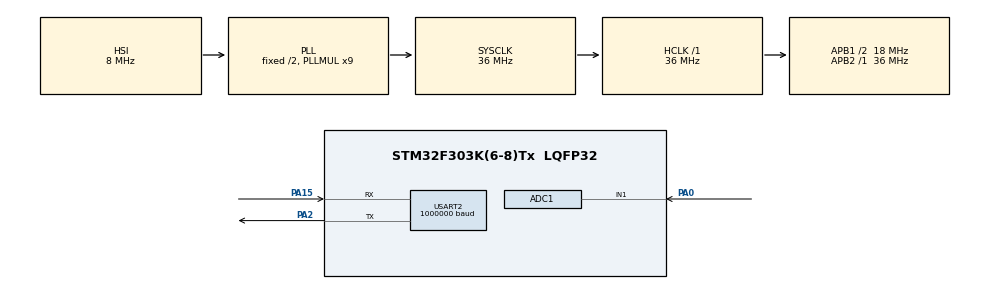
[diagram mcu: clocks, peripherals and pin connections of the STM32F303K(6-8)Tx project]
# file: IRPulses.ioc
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ADC1.Channel-0\#ChannelRegularConversion=ADC_CHANNEL_1
ADC1.ExternalTrigConv=ADC_EXTERNALTRIGCONV_T1_TRGO
ADC1.NbrOfConversionFlag=1
ADC1.Offset-0\#ChannelRegularConversion=0
ADC1.OffsetNumber-0\#ChannelRegularConversion=ADC_OFFSET_NONE
ADC1.Rank-0\#ChannelRegularConversion=1
ADC1.Resolution=ADC_RESOLUTION_8B
ADC1.SamplingTime-0\#ChannelRegularConversion=ADC_SAMPLETIME_1CYCLE_5
ADC1.master=1
Dma.ADC1.0.Direction=DMA_PERIPH_TO_MEMORY
Dma.ADC1.0.Instance=DMA1_Channel1
Dma.ADC1.0.MemDataAlignment=DMA_MDATAALIGN_HALFWORD
Dma.ADC1.0.MemInc=DMA_MINC_ENABLE
Dma.ADC1.0.Mode=DMA_NORMAL
Dma.ADC1.0.PeriphDataAlignment=DMA_PDATAALIGN_HALFWORD
Dma.ADC1.0.PeriphInc=DMA_PINC_DISABLE
Dma.ADC1.0.Priority=DMA_PRIORITY_LOW
Dma.Request0=ADC1
Mcu.Family=STM32F3
Mcu.Name=STM32F303K(6-8)Tx
Mcu.Package=LQFP32
NVIC.ADC1_2_IRQn=true\:0\:0\:false\:false\:true\:true\:true\:true
NVIC.DMA1_Channel1_IRQn=true\:0\:0\:false\:false\:true\:false\:true\:true
NVIC.PriorityGroup=NVIC_PRIORITYGROUP_4
PA0.Mode=IN1-Single-Ended
PA0.Signal=ADC1_IN1
PA13.Mode=Serial_Wire
PA13.Signal=SYS_JTMS-SWDIO
PA14.Mode=Serial_Wire
PA14.Signal=SYS_JTCK-SWCLK
PA15.Mode=Asynchronous
PA15.Signal=USART2_RX
PA2.Mode=Asynchronous
PA2.Signal=USART2_TX
PF0\ /\ OSC_IN.Mode=HSE-External-Clock-Source
PF0\ /\ OSC_IN.Signal=RCC_OSC_IN
ProjectManager.HeapSize=0x200
ProjectManager.StackSize=0x400
ProjectManager.TargetToolchain=Makefile
RCC.AHBFreq_Value=36000000
RCC.APB1CLKDivider=RCC_HCLK_DIV2
RCC.APB1Freq_Value=18000000
RCC.APB1TimFreq_Value=36000000
RCC.APB2Freq_Value=36000000
RCC.APB2TimFreq_Value=36000000
RCC.CortexFreq_Value=36000000
RCC.HCLKFreq_Value=36000000
RCC.HSE_VALUE=8000000
RCC.HSI_VALUE=8000000
RCC.PLLMUL=RCC_PLL_MUL9
RCC.SYSCLKFreq_VALUE=36000000
RCC.SYSCLKSourceVirtual=RCC_SYSCLKSOURCE_PLLCLK
TIM1.Period=19
TIM1.Prescaler=35
TIM1.TIM_MasterOutputTrigger=TIM_TRGO_UPDATE
USART2.BaudRate=1000000
USART2.VirtualMode-Asynchronous=VM_ASYNC
VP_TIM1_VS_ClockSourceINT.Mode=Internal
board=custom

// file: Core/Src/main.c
/* USER CODE BEGIN Header */
/**
 ******************************************************************************
 * @file           : main.c
 * @brief          : Main program body
 ******************************************************************************
 * @attention
 *
 * Copyright (c) 2022 STMicroelectronics.
 * All rights reserved.
 *
 * This software is licensed under terms that can be found in the LICENSE file
 * in the root directory of this software component.
 * If no LICENSE file comes with this software, it is provided AS-IS.
 *
 ******************************************************************************
 */
/* USER CODE END Header */
#include "main.h"
#include "stm32f3xx_hal_adc.h"
#include "stm32f3xx_hal_adc_ex.h"
#include "stm32f3xx_hal_tim.h"

ADC_HandleTypeDef hadc1;
DMA_HandleTypeDef hdma_adc1;

TIM_HandleTypeDef htim1;

UART_HandleTypeDef huart2;

void SystemClock_Config(void);
static void MX_GPIO_Init(void);
static void MX_DMA_Init(void);
static void MX_USART2_UART_Init(void);
static void MX_ADC1_Init(void);
static void MX_TIM1_Init(void);

/* USER CODE BEGIN 0 */
uint16_t buf[1024];
uint32_t integral;
uint8_t complete;
uint8_t busy;

void HAL_ADC_ConvCpltCallback(ADC_HandleTypeDef *hadc) {
	complete = 1;
}
/* USER CODE END 0 */

int main(void) {

	/* MCU
	 * Configuration--------------------------------------------------------*/

	/* Reset of all peripherals, Initializes the Flash interface and the
	 * Systick. */
	HAL_Init();

	/* Configure the system clock */
	SystemClock_Config();

	/* Initialize all configured peripherals */
	MX_GPIO_Init();
	MX_DMA_Init();
	MX_USART2_UART_Init();
	MX_ADC1_Init();
	MX_TIM1_Init();

	/* Infinite loop */
	/* USER CODE BEGIN WHILE */
	/* __HAL_TIM_SET_PRESCALER(&htim1, */
	/* 						35000); // slow down the timer for testing purposes */

	hadc1.Init.ExternalTrigConv = ADC_SOFTWARE_START;
	HAL_ADC_Init(&hadc1);
	while (1) {
		if (complete) {
			HAL_TIM_Base_Stop(&htim1);
			complete = 0;
			busy = 0;
			integral = 0;
			for (uint16_t i = 0; i < sizeof(buf) / sizeof(*buf); i++) {
				integral += buf[i];
			}
			hadc1.Init.ExternalTrigConv = ADC_SOFTWARE_START;
			HAL_ADC_Init(&hadc1);
			__BKPT();
		} else if (!busy) {
			HAL_ADC_Start(&hadc1);
			HAL_ADC_PollForConversion(&hadc1, 1500);
			uint16_t val = HAL_ADC_GetValue(&hadc1);

			if (val >= 32) {
				busy = 1;
				hadc1.Init.ExternalTrigConv = ADC_EXTERNALTRIGCONV_T1_TRGO;
				HAL_ADC_Init(&hadc1);
				HAL_ADC_Start_DMA(&hadc1, buf, 1024);
				HAL_TIM_Base_Start(&htim1);
			}
		}

		/* USER CODE END WHILE */

	}
}

void SystemClock_Config(void) {
	RCC_OscInitTypeDef RCC_OscInitStruct = {0};
	RCC_ClkInitTypeDef RCC_ClkInitStruct = {0};
	RCC_PeriphCLKInitTypeDef PeriphClkInit = {0};

	/** Initializes the RCC Oscillators according to the specified parameters
	 * in the RCC_OscInitTypeDef structure.
	 */
	RCC_OscInitStruct.OscillatorType = RCC_OSCILLATORTYPE_HSI;
	RCC_OscInitStruct.HSIState = RCC_HSI_ON;
	RCC_OscInitStruct.HSICalibrationValue = RCC_HSICALIBRATION_DEFAULT;
	RCC_OscInitStruct.PLL.PLLState = RCC_PLL_ON;
	RCC_OscInitStruct.PLL.PLLSource = RCC_PLLSOURCE_HSI;
	RCC_OscInitStruct.PLL.PLLMUL = RCC_PLL_MUL9;
	if (HAL_RCC_OscConfig(&RCC_OscInitStruct) != HAL_OK) {
		Error_Handler();
	}

	/** Initializes the CPU, AHB and APB buses clocks
	 */
	RCC_ClkInitStruct.ClockType = RCC_CLOCKTYPE_HCLK | RCC_CLOCKTYPE_SYSCLK |
								  RCC_CLOCKTYPE_PCLK1 | RCC_CLOCKTYPE_PCLK2;
	RCC_ClkInitStruct.SYSCLKSource = RCC_SYSCLKSOURCE_PLLCLK;
	RCC_ClkInitStruct.AHBCLKDivider = RCC_SYSCLK_DIV1;
	RCC_ClkInitStruct.APB1CLKDivider = RCC_HCLK_DIV2;
	RCC_ClkInitStruct.APB2CLKDivider = RCC_HCLK_DIV1;

	if (HAL_RCC_ClockConfig(&RCC_ClkInitStruct, FLASH_LATENCY_1) != HAL_OK) {
		Error_Handler();
	}
	PeriphClkInit.PeriphClockSelection =
		RCC_PERIPHCLK_TIM1 | RCC_PERIPHCLK_ADC12;
	PeriphClkInit.Adc12ClockSelection = RCC_ADC12PLLCLK_DIV1;
	PeriphClkInit.Tim1ClockSelection = RCC_TIM1CLK_HCLK;
	if (HAL_RCCEx_PeriphCLKConfig(&PeriphClkInit) != HAL_OK) {
		Error_Handler();
	}
}

static void MX_ADC1_Init(void) {

	ADC_MultiModeTypeDef multimode = {0};
	ADC_ChannelConfTypeDef sConfig = {0};

	/** Common config
	 */
	hadc1.Instance = ADC1;
	hadc1.Init.ClockPrescaler = ADC_CLOCK_ASYNC_DIV1;
	hadc1.Init.Resolution = ADC_RESOLUTION_8B;
	hadc1.Init.ScanConvMode = ADC_SCAN_DISABLE;
	hadc1.Init.ContinuousConvMode = DISABLE;
	hadc1.Init.DiscontinuousConvMode = DISABLE;
	hadc1.Init.ExternalTrigConvEdge = ADC_EXTERNALTRIGCONVEDGE_RISING;
	hadc1.Init.ExternalTrigConv = ADC_EXTERNALTRIGCONV_T1_TRGO;
	hadc1.Init.DataAlign = ADC_DATAALIGN_RIGHT;
	hadc1.Init.NbrOfConversion = 1;
	hadc1.Init.DMAContinuousRequests = DISABLE;
	hadc1.Init.EOCSelection = ADC_EOC_SINGLE_CONV;
	hadc1.Init.LowPowerAutoWait = DISABLE;
	hadc1.Init.Overrun = ADC_OVR_DATA_OVERWRITTEN;
	if (HAL_ADC_Init(&hadc1) != HAL_OK) {
		Error_Handler();
	}

	/** Configure the ADC multi-mode
	 */
	multimode.Mode = ADC_MODE_INDEPENDENT;
	if (HAL_ADCEx_MultiModeConfigChannel(&hadc1, &multimode) != HAL_OK) {
		Error_Handler();
	}

	/** Configure Regular Channel
	 */
	sConfig.Channel = ADC_CHANNEL_1;
	sConfig.Rank = ADC_REGULAR_RANK_1;
	sConfig.SingleDiff = ADC_SINGLE_ENDED;
	sConfig.SamplingTime = ADC_SAMPLETIME_1CYCLE_5;
	sConfig.OffsetNumber = ADC_OFFSET_NONE;
	sConfig.Offset = 0;
	if (HAL_ADC_ConfigChannel(&hadc1, &sConfig) != HAL_OK) {
		Error_Handler();
	}
}

static void MX_TIM1_Init(void) {

	TIM_ClockConfigTypeDef sClockSourceConfig = {0};
	TIM_MasterConfigTypeDef sMasterConfig = {0};

	htim1.Instance = TIM1;
	htim1.Init.Prescaler = 35;
	htim1.Init.CounterMode = TIM_COUNTERMODE_UP;
	htim1.Init.Period = 19;
	htim1.Init.ClockDivision = TIM_CLOCKDIVISION_DIV1;
	htim1.Init.RepetitionCounter = 0;
	htim1.Init.AutoReloadPreload = TIM_AUTORELOAD_PRELOAD_DISABLE;
	if (HAL_TIM_Base_Init(&htim1) != HAL_OK) {
		Error_Handler();
	}
	sClockSourceConfig.ClockSource = TIM_CLOCKSOURCE_INTERNAL;
	if (HAL_TIM_ConfigClockSource(&htim1, &sClockSourceConfig) != HAL_OK) {
		Error_Handler();
	}
	sMasterConfig.MasterOutputTrigger = TIM_TRGO_UPDATE;
	sMasterConfig.MasterOutputTrigger2 = TIM_TRGO2_RESET;
	sMasterConfig.MasterSlaveMode = TIM_MASTERSLAVEMODE_DISABLE;
	if (HAL_TIMEx_MasterConfigSynchronization(&htim1, &sMasterConfig) !=
		HAL_OK) {
		Error_Handler();
	}
}

static void MX_USART2_UART_Init(void) {

	huart2.Instance = USART2;
	huart2.Init.BaudRate = 1000000;
	huart2.Init.WordLength = UART_WORDLENGTH_8B;
	huart2.Init.StopBits = UART_STOPBITS_1;
	huart2.Init.Parity = UART_PARITY_NONE;
	huart2.Init.Mode = UART_MODE_TX_RX;
	huart2.Init.HwFlowCtl = UART_HWCONTROL_NONE;
	huart2.Init.OverSampling = UART_OVERSAMPLING_16;
	huart2.Init.OneBitSampling = UART_ONE_BIT_SAMPLE_DISABLE;
	huart2.AdvancedInit.AdvFeatureInit = UART_ADVFEATURE_NO_INIT;
	if (HAL_UART_Init(&huart2) != HAL_OK) {
		Error_Handler();
	}
}

static void MX_DMA_Init(void) {

	/* DMA controller clock enable */
	__HAL_RCC_DMA1_CLK_ENABLE();

	/* DMA interrupt init */
	/* DMA1_Channel1_IRQn interrupt configuration */
	HAL_NVIC_SetPriority(DMA1_Channel1_IRQn, 0, 0);
	HAL_NVIC_EnableIRQ(DMA1_Channel1_IRQn);
}

static void MX_GPIO_Init(void) {

	/* GPIO Ports Clock Enable */
	__HAL_RCC_GPIOF_CLK_ENABLE();
	__HAL_RCC_GPIOA_CLK_ENABLE();
}

void Error_Handler(void) {
	/* USER CODE BEGIN Error_Handler_Debug */
	/* User can add his own implementation to report the HAL error return state
	 */
	__disable_irq();
	while (1) {
	}
	/* USER CODE END Error_Handler_Debug */
}

#ifdef USE_FULL_ASSERT
/**
 * @brief  Reports the name of the source file and the source line number
 *         where the assert_param error has occurred.
 * @param  file: pointer to the source file name
 * @param  line: assert_param error line source number
 * @retval None
 */
void assert_failed(uint8_t *file, uint32_t line) {
	/* USER CODE BEGIN 6 */
	/* User can add his own implementation to report the file name and line
	   number, ex: printf("Wrong parameters value: file %s on line %d\r\n",
	   file, line) */
	/* USER CODE END 6 */
}
#endif /* USE_FULL_ASSERT */
